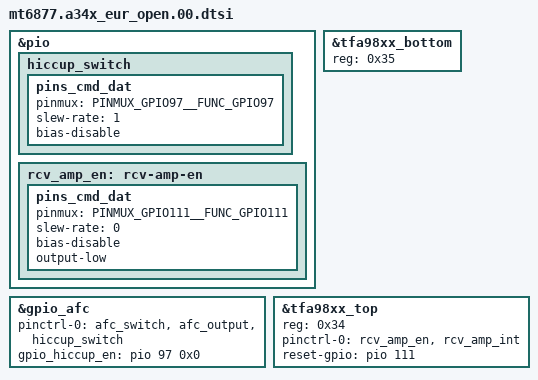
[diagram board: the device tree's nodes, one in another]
/*
 * Generated by Samsung
 * If these files should be changed, then please make a sync with MTK
*/

#include "mt6877-a34x_common.dtsi"
#include "mt6877-a34x_camera_00.dtsi"

&pio {
	hiccup_switch: hiccup_switch {
		pins_cmd_dat {
			pinmux = <PINMUX_GPIO97__FUNC_GPIO97>;
			slew-rate = <1>;
			bias-disable;
		};
	};

	rcv_amp_en: rcv-amp-en {
		pins_cmd_dat {
			pinmux = <PINMUX_GPIO111__FUNC_GPIO111>;
			slew-rate = <0>;
			bias-disable;
			output-low;
		};
	};
};

&gpio_afc {
	pinctrl-names = "default";
	pinctrl-0 = <&afc_switch &afc_output &hiccup_switch>;
	gpio_hiccup_en = <&pio 97 0x0>;
};

/*End of this file, DO NOT ADD ANYTHING HERE*/

&tfa98xx_bottom {
	reg = <0x35>;
};

&tfa98xx_top {
	reg = <0x34>;
	pinctrl-0 = <&rcv_amp_en &rcv_amp_int>;
	reset-gpio = <&pio 111 0>;
};
